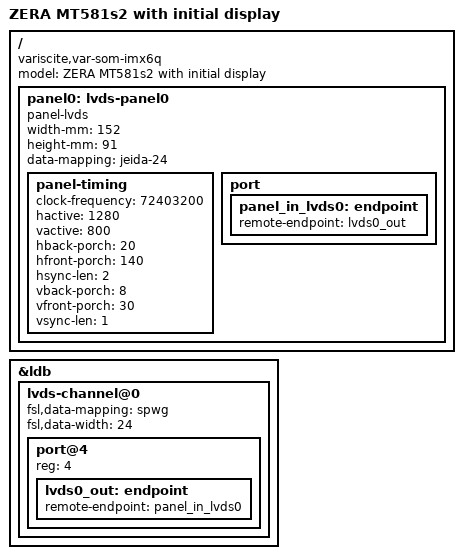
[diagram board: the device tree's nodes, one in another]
// SPDX-License-Identifier: GPL-2.0+
/*
 * Support for Zera MT581 & friends display
 *
 * Copyright 2026 ZERA GmbH
 */

/dts-v1/;

#include "imx6q-var-som-zera.dtsi"

/ {
	model = "ZERA MT581s2 with initial display";
	compatible = "variscite,var-som-imx6q", "fsl,imx6q";

	panel0: lvds-panel0 {
		compatible = "panel-lvds";
		width-mm = <152>;
		height-mm = <91>;
		data-mapping = "jeida-24";

		panel-timing {
			clock-frequency = <72403200>;
			hactive = <1280>;
			vactive = <800>;
			hback-porch = <20>;
			hfront-porch = <140>;
			hsync-len = <2>;
			vback-porch = <8>;
			vfront-porch = <30>;
			vsync-len = <1>;
		};
		port {
			panel_in_lvds0: endpoint {
				remote-endpoint = <&lvds0_out>;
			};
		};
	};
};

&ldb {
	status = "okay";
	lvds-channel@0 {
		fsl,data-mapping = "spwg";
		fsl,data-width = <24>;
		status = "okay";
		port@4 {
			reg = <4>;
			lvds0_out: endpoint {
				remote-endpoint = <&panel_in_lvds0>;
			};
		};
	};
};
